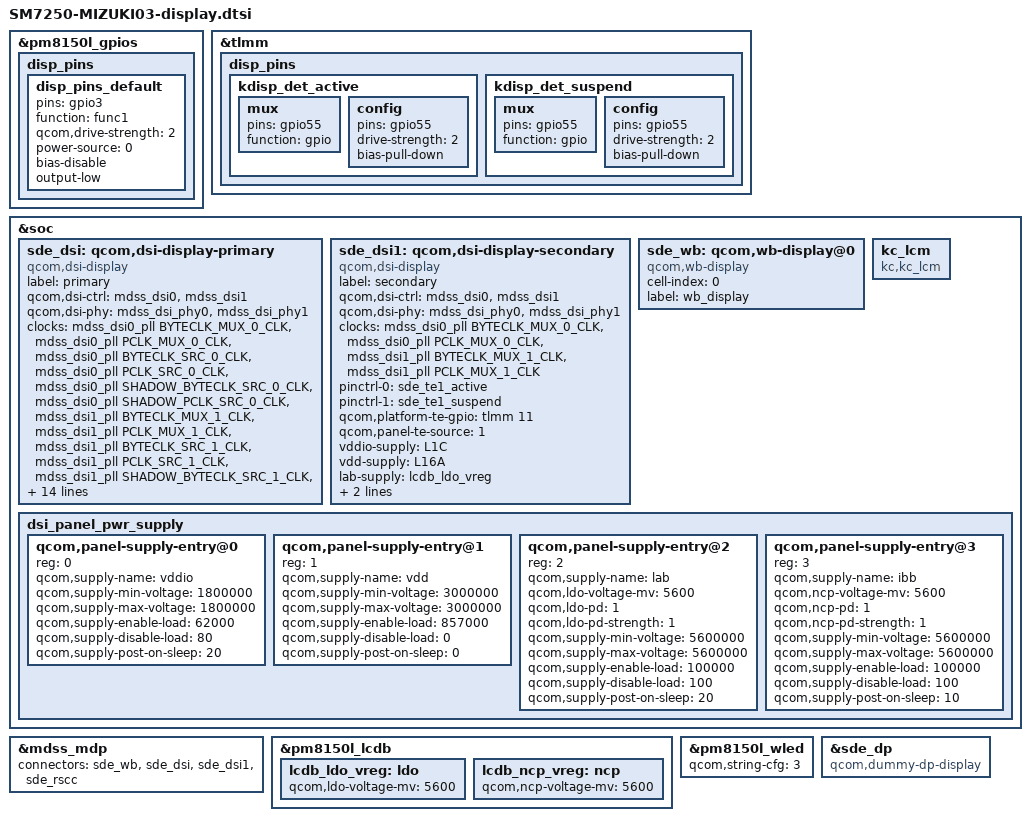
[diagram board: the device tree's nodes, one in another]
#include <dt-bindings/gpio/gpio.h>
#include <dt-bindings/clock/mdss-7nm-pll-clk.h>

#include "dsi-panel-kc-jdi-fhd-video-panel.dtsi"
#include "dsi-panel-kc-auo-fhd-video-panel2.dtsi"


&pm8150l_gpios {
	disp_pins {
		disp_pins_default: disp_pins_default {
			pins = "gpio3";
			function = "func1";
			qcom,drive-strength = <2>;
			power-source = <0>;
			bias-disable;
			output-low;
		};
	};
};

&tlmm {
	disp_pins {
		kdisp_det_active: kdisp_det_active {
			mux {
				pins = "gpio55";
				function = "gpio";
			};

			config {
				pins = "gpio55";
				drive-strength = <2>;   /* 2 mA */
				bias-pull-down;         /* PULL DOWN */
			};
		};

		kdisp_det_suspend: kdisp_det_suspend {
			mux {
				pins = "gpio55";
				function = "gpio";
			};

			config {
				pins = "gpio55";
				drive-strength = <2>;   /* 2 mA */
				bias-pull-down;         /* PULL DOWN */
			};
		};
	};
};

&soc {
	sde_dsi: qcom,dsi-display-primary {
		compatible = "qcom,dsi-display";
		label = "primary";

		qcom,dsi-ctrl = <&mdss_dsi0 &mdss_dsi1>;
		qcom,dsi-phy = <&mdss_dsi_phy0 &mdss_dsi_phy1>;

		clocks = <&mdss_dsi0_pll BYTECLK_MUX_0_CLK>,
			 <&mdss_dsi0_pll PCLK_MUX_0_CLK>,
			 <&mdss_dsi0_pll BYTECLK_SRC_0_CLK>,
			 <&mdss_dsi0_pll PCLK_SRC_0_CLK>,
			 <&mdss_dsi0_pll SHADOW_BYTECLK_SRC_0_CLK>,
			 <&mdss_dsi0_pll SHADOW_PCLK_SRC_0_CLK>,
			 <&mdss_dsi1_pll BYTECLK_MUX_1_CLK>,
			 <&mdss_dsi1_pll PCLK_MUX_1_CLK>,
			 <&mdss_dsi1_pll BYTECLK_SRC_1_CLK>,
			 <&mdss_dsi1_pll PCLK_SRC_1_CLK>,
			 <&mdss_dsi1_pll SHADOW_BYTECLK_SRC_1_CLK>,
			 <&mdss_dsi1_pll SHADOW_PCLK_SRC_1_CLK>;
		clock-names = "mux_byte_clk0", "mux_pixel_clk0",
				"src_byte_clk0", "src_pixel_clk0",
				"shadow_byte_clk0", "shadow_pixel_clk0",
				"mux_byte_clk1", "mux_pixel_clk1",
				"src_byte_clk1", "src_pixel_clk1",
				"shadow_byte_clk1", "shadow_pixel_clk1";

		pinctrl-names = "panel_active", "panel_suspend";
		pinctrl-0 = <&sde_te_active &kdisp_det_active &disp_pins_default>;
		pinctrl-1 = <&sde_te_suspend &kdisp_det_suspend>;

		qcom,platform-te-gpio = <&tlmm 10 0>;
		kc,ts-irq-gpio = <&tlmm 9 0x2008>;
		kc,ts-reset-gpio = <&tlmm 8 0x00>;
		qcom,panel-te-source = <0>;

		vddio-supply = <&L1C>;
		vdd-supply = <&L16A>;

		lab-supply = <&lcdb_ldo_vreg>;
		ibb-supply = <&lcdb_ncp_vreg>;

		qcom,mdp = <&mdss_mdp>;
	};

	sde_dsi1: qcom,dsi-display-secondary {
		compatible = "qcom,dsi-display";
		label = "secondary";

		qcom,dsi-ctrl = <&mdss_dsi0 &mdss_dsi1>;
		qcom,dsi-phy = <&mdss_dsi_phy0 &mdss_dsi_phy1>;

		clocks = <&mdss_dsi0_pll BYTECLK_MUX_0_CLK>,
			 <&mdss_dsi0_pll PCLK_MUX_0_CLK>,
			 <&mdss_dsi1_pll BYTECLK_MUX_1_CLK>,
			 <&mdss_dsi1_pll PCLK_MUX_1_CLK>;
		clock-names = "mux_byte_clk0", "mux_pixel_clk0",
			      "mux_byte_clk1", "mux_pixel_clk1";

		pinctrl-names = "panel_active", "panel_suspend";
		pinctrl-0 = <&sde_te1_active>;
		pinctrl-1 = <&sde_te1_suspend>;

		qcom,platform-te-gpio = <&tlmm 11 0>;
		qcom,panel-te-source = <1>;

		vddio-supply = <&L1C>;
		vdd-supply = <&L16A>;

		lab-supply = <&lcdb_ldo_vreg>;
		ibb-supply = <&lcdb_ncp_vreg>;

		qcom,mdp = <&mdss_mdp>;
	};

	sde_wb: qcom,wb-display@0 {
		compatible = "qcom,wb-display";
		cell-index = <0>;
		label = "wb_display";
	};
};

&mdss_mdp {
	connectors = <&sde_wb &sde_dsi &sde_dsi1 &sde_rscc>;
};

&soc {
	kc_lcm: kc_lcm {
		compatible = "kc,kc_lcm";
	};
};


&soc {
	dsi_panel_pwr_supply: dsi_panel_pwr_supply {
		#address-cells = <1>;
		#size-cells = <0>;

		qcom,panel-supply-entry@0 {
			reg = <0>;
			qcom,supply-name = "vddio";
			qcom,supply-min-voltage = <1800000>;
			qcom,supply-max-voltage = <1800000>;
			qcom,supply-enable-load = <62000>;
			qcom,supply-disable-load = <80>;
			qcom,supply-post-on-sleep = <20>;
		};

		qcom,panel-supply-entry@1 {
			reg = <1>;
			qcom,supply-name = "vdd";
			qcom,supply-min-voltage = <3000000>;
			qcom,supply-max-voltage = <3000000>;
			qcom,supply-enable-load = <857000>;
			qcom,supply-disable-load = <0>;
			qcom,supply-post-on-sleep = <0>;
		};

		qcom,panel-supply-entry@2 {
			reg = <2>;
			qcom,supply-name = "lab";
			//test
			qcom,ldo-voltage-mv = <5600>;
			qcom,ldo-pd = <1>;
			qcom,ldo-pd-strength = <1>;
			
			qcom,supply-min-voltage = <5600000>;
			qcom,supply-max-voltage = <5600000>;
			qcom,supply-enable-load = <100000>;
			qcom,supply-disable-load = <100>;
			qcom,supply-post-on-sleep = <20>;
			
		};

		qcom,panel-supply-entry@3 {
			reg = <3>;
			qcom,supply-name = "ibb";
			//test
			
			qcom,ncp-voltage-mv = <5600>;
			qcom,ncp-pd = <1>;
			qcom,ncp-pd-strength = <1>;
		
			qcom,supply-min-voltage = <5600000>;
			qcom,supply-max-voltage = <5600000>;
			qcom,supply-enable-load = <100000>;
			qcom,supply-disable-load = <100>;
			qcom,supply-post-on-sleep = <10>;
			
		};

	};
};


&pm8150l_lcdb {
	status = "ok";
	lcdb_ldo_vreg: ldo {
		qcom,ldo-voltage-mv = <5600>;
		/*
		qcom,ldo-pd = <1>;
		qcom,ldo-pd-strength = <1>;
		*/
	};
	lcdb_ncp_vreg: ncp {
		qcom,ncp-voltage-mv = <5600>;
		/*
		qcom,ncp-pd = <1>;
		qcom,ncp-pd-strength = <1>;
		qcom,ncp-ilim-ma = <500>;
		*/
	};
};

&pm8150l_wled{
	qcom,string-cfg = <3>;
	/delete-property/ qcom,auto-calibration;
	status = "okay";
};

&sde_dp{
	compatible = "qcom,dummy-dp-display";
};

&sde_dsi {
	qcom,dsi-default-panel = <&dsi_auo_fhd_2160_video>;
};
